# STM32N655 register map
File version: 1.0
CPU: CM55 r0p1, little endian, no MPU, FPU, vendor SysTick, 8 interrupt priority bits
Registers are 32-bit, read-write, reset 0x0 unless marked. A register's access mark holds for its fields unless they carry their own. Offsets are from the block's base; [hi:lo] are bit positions; {n}, {i} and the like mark numbered series.

## HASH — HASH register bank (full SHA-2/SHA-3)
Base 0x44020400
Same registers: HASH_S 0x54020400
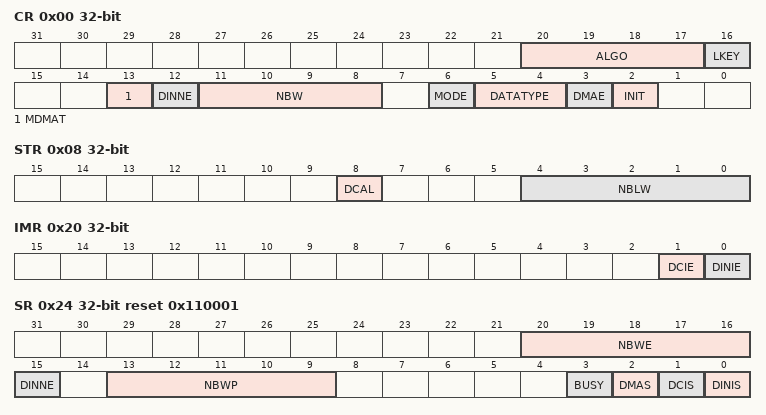
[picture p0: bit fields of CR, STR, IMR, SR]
0x00 CR access per field — HASH control register
  [20:17] ALGO rw — Algorithm selection
  [16] LKEY rw — Long key selection
  [13] MDMAT rw — Multiple DMA transfers
  [12] DINNE ro — DIN not empty
  [11:8] NBW ro — Number of words already pushed
  [6] MODE rw — Mode selection
  [5:4] DATATYPE rw — Data type selection
  [3] DMAE rw — DMA enable
  [2] INIT rw — Initialize message digest calculation
0x04 DIN wo — HASH data input register
  [31:0] DATAIN — Data input
0x08 STR — HASH start register
  [8] DCAL — Digest calculation
  [4:0] NBLW — Number of valid bits in the last word
{0xC+4i} HRA{i} ro (i=0..4) — HASH aliased digest register {i}
  [31:0] H{i} — Hash data x
0x20 IMR — HASH interrupt enable register
  [1] DCIE — Digest calculation completion interrupt enable
  [0] DINIE — Data input interrupt enable
0x24 SR access per field reset 0x110001 — HASH status register
  [20:16] NBWE ro — Number of words expected
  [15] DINNE ro — DIN not empty
  [13:9] NBWP ro — Number of words already pushed
  [3] BUSY ro — Busy bit
  [2] DMAS ro — DMA Status
  [1] DCIS rw — Digest calculation completion interrupt status
  [0] DINIS rw — Data input interrupt status
{0xF8+4i} CSR{i} (i=0..102) — HASH context swap register {i}
  [31:0] CS{i} — Context swap x
{0x310+4i} HR{i} ro (i=0..4) — HASH digest register {i}
  [31:0] H{i} — Hash data x
{0x310+4i} HR{i} ro (i=5..15) — HASH supplementary digest register {i}
  [31:0] H{i} — Hash data x

## HDP — Hardware debug port
Base 0x46000800
Same registers: HDP_S 0x56000800
0x00 CTRL — HDP control register
  [0] EN — Enable HDP, valid if enabled in BSEC
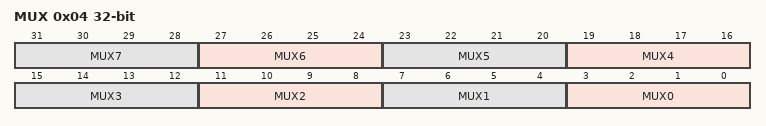
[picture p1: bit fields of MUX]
0x04 MUX — HDP multiplexer control register
  [4n+3:4n] MUX{n} (n=0..7) — Select the HDPy output among the 16 available signals
0x10 VAL ro — HDP read back value register
  [7:0] HDPVAL — Value of the HDP signals
0x14 GPOSET wo — HDP general-purpose output set register
  [7:0] HDPGPOSET — When a bit is written to 1, the corresponding HDP GPO is set
0x18 GPOCLR wo — HDP general purpose output clear register
  [7:0] HDPGPOCLR — When a bit is written to 1, the corresponding HDP GPO is cleared.
0x1C GPOVAL — HDP general purpose output value register
  [7:0] HDPGPOVAL — When written, define the value of the HDP GPO.

## IAC — Illegal access controller
Base 0x44025000
Same registers: IAC_S 0x54025000
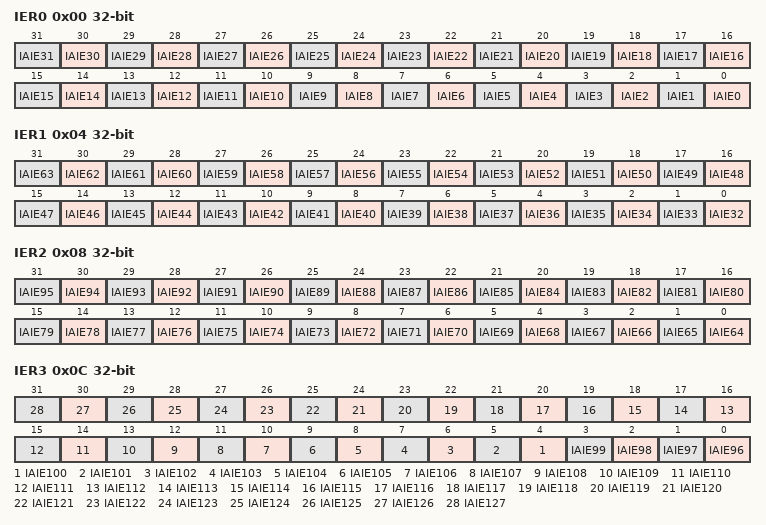
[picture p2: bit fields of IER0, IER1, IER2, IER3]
0x00 IER0 — IAC interrupt enable register 0
  [n] IAIE{n} (n=0..31) — illegal access interrupt enable for peripheral {n}
0x04 IER1 — IAC interrupt enable register 1
  [n-32] IAIE{n} (n=32..63) — illegal access interrupt enable for peripheral {n}
0x08 IER2 — IAC interrupt enable register 2
  [n-64] IAIE{n} (n=64..95) — illegal access interrupt enable for peripheral {n}
0x0C IER3 — IAC interrupt enable register 3
  [n-96] IAIE{n} (n=96..127) — illegal access interrupt enable for peripheral {n}
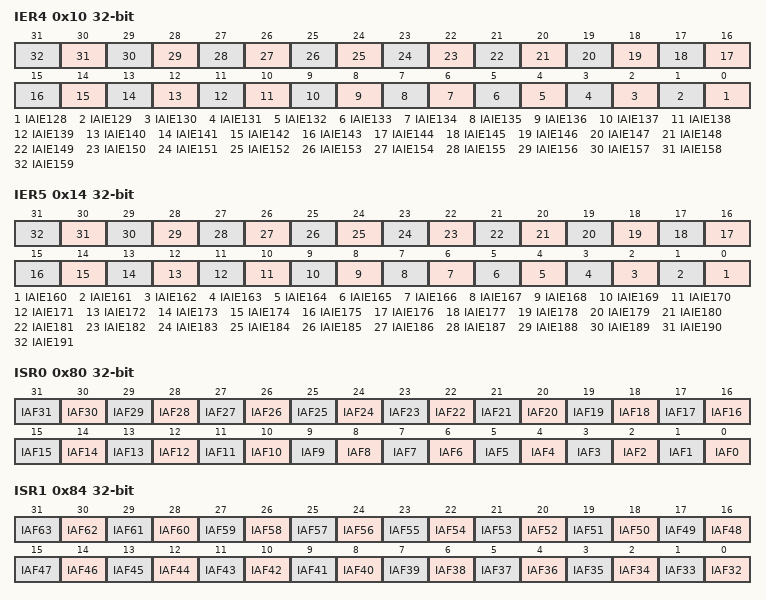
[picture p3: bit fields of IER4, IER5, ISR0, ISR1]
0x10 IER4 — IAC interrupt enable register 4
  [n-128] IAIE{n} (n=128..159) — illegal access interrupt enable for peripheral {n}
0x14 IER5 — IAC interrupt enable register 5
  [n-160] IAIE{n} (n=160..191) — illegal access interrupt enable for peripheral {n}
0x80 ISR0 ro — IAC interrupt status register 0
  [n] IAF{n} (n=0..31) — illegal access interrupt enable for peripheral {n}
0x84 ISR1 ro — IAC interrupt status register 1
  [n-32] IAF{n} (n=32..63) — illegal access interrupt enable for peripheral {n}
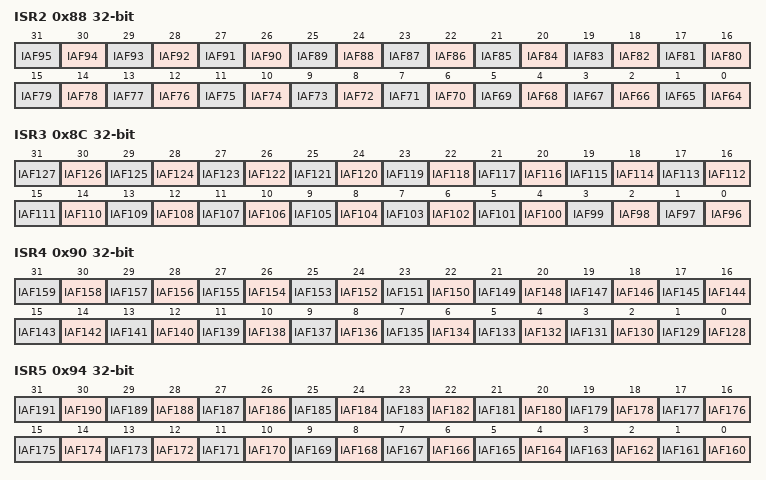
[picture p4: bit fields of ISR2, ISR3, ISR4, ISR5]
0x88 ISR2 ro — IAC interrupt status register 2
  [n-64] IAF{n} (n=64..95) — illegal access interrupt enable for peripheral {n}
0x8C ISR3 ro — IAC interrupt status register 3
  [n-96] IAF{n} (n=96..127) — illegal access interrupt enable for peripheral {n}
0x90 ISR4 ro — IAC interrupt status register 4
  [n-128] IAF{n} (n=128..159) — illegal access interrupt enable for peripheral {n}
0x94 ISR5 ro — IAC interrupt status register 5
  [n-160] IAF{n} (n=160..191) — illegal access interrupt enable for peripheral {n}
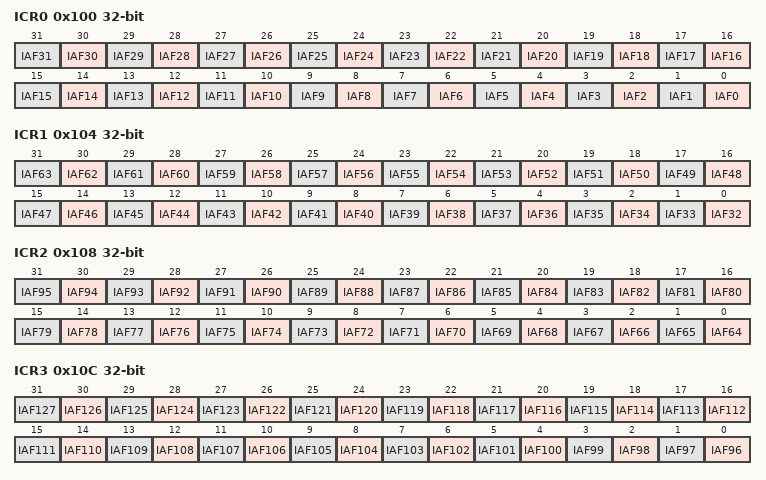
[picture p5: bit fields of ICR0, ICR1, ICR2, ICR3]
0x100 ICR0 wo — IAC interrupt clear register 0
  [n] IAF{n} (n=0..31) — illegal access flag clear for peripheral {n}
0x104 ICR1 wo — IAC interrupt clear register 1
  [n-32] IAF{n} (n=32..63) — illegal access flag clear for peripheral {n}
0x108 ICR2 wo — IAC interrupt clear register 2
  [n-64] IAF{n} (n=64..95) — illegal access flag clear for peripheral {n}
0x10C ICR3 wo — IAC interrupt clear register 3
  [n-96] IAF{n} (n=96..127) — illegal access flag clear for peripheral {n}
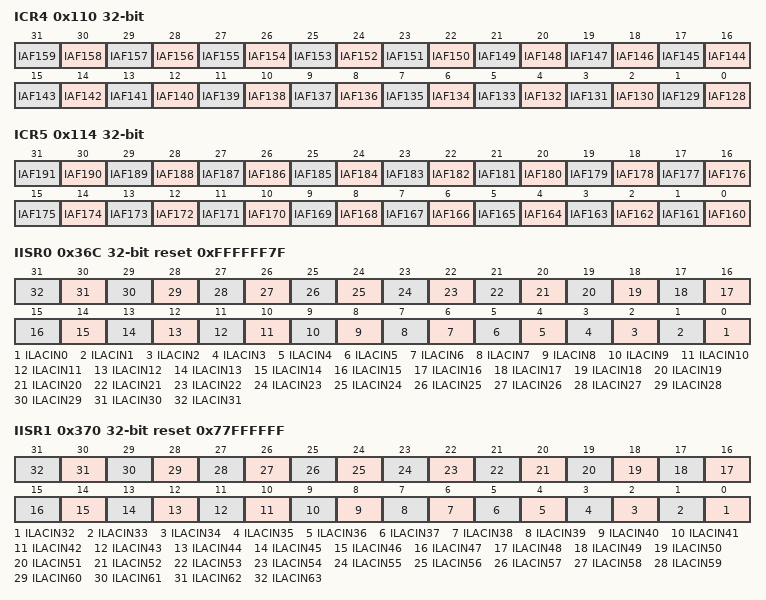
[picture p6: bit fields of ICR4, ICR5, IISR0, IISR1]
0x110 ICR4 wo — IAC interrupt clear register 4
  [n-128] IAF{n} (n=128..159) — illegal access flag clear for peripheral {n}
0x114 ICR5 wo — IAC interrupt clear register 5
  [n-160] IAF{n} (n=160..191) — illegal access flag clear for peripheral {n}
0x36C IISR0 ro reset 0xFFFFFF7F — IAC ILAC input status register 0
  [n] ILACIN{n} (n=0..31) — illegal access input {n}
0x370 IISR1 ro reset 0x77FFFFFF — IAC ILAC input status register 1
  [n-32] ILACIN{n} (n=32..63) — illegal access input {n}
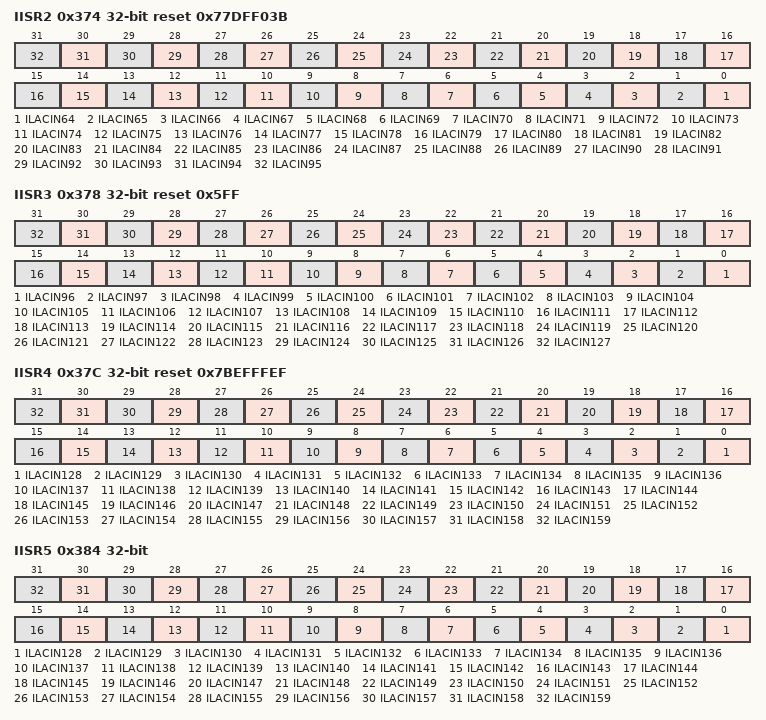
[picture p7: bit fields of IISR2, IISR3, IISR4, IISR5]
0x374 IISR2 ro reset 0x77DFF03B — IAC ILAC input status register 2
  [n-64] ILACIN{n} (n=64..95) — illegal access input {n}
0x378 IISR3 ro reset 0x5FF — IAC ILAC input status register 3
  [n-96] ILACIN{n} (n=96..127) — illegal access input {n}
0x37C IISR4 ro reset 0x7BEFFFEF — IAC ILAC input status register 4
  [n-128] ILACIN{n} (n=128..159) — illegal access input {n}
0x384 IISR5 ro — IAC ILAC input status register 5
  [n-128] ILACIN{n} (n=128..159) — illegal access input {n}
